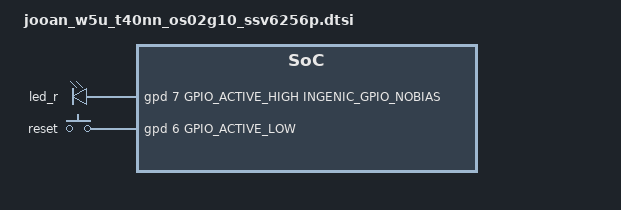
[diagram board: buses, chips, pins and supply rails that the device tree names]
// Jooan W5U (T40NN, OS02G10, SSV6256P) per-board GPIO definitions.
// Injected into the kernel 4.4+ device tree; ignored on 3.10.

#include <dt-bindings/gpio/gpio.h>
#include <dt-bindings/input/input.h>
#include <dt-bindings/pinctrl/ingenic-pinctrl.h>

/ {
	gpio-leds {
		compatible = "gpio-leds";

		led_r {
			label = "led_r";
			gpios = <&gpd 7 GPIO_ACTIVE_HIGH INGENIC_GPIO_NOBIAS>;
			default-state = "off";
		};
	};
};

/* Card detect; the family tree carries the reference pin. */
&msc0 {
	ingenic,cd-gpios = <&gpc 6 GPIO_ACTIVE_LOW INGENIC_GPIO_PULLUP>;
};

/ {
	gpio-keys {
		compatible = "gpio-keys";
		label = "gpio-keys";

		reset {
			label = "reset";
			linux,code = <KEY_ENTER>;
			gpios = <&gpd 6 GPIO_ACTIVE_LOW INGENIC_GPIO_PULLUP>;
		};
	};
};
